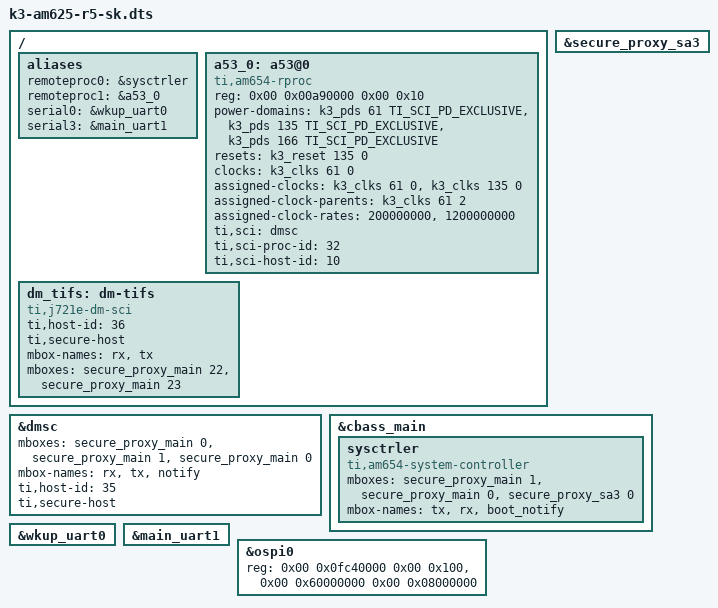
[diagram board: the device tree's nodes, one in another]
// SPDX-License-Identifier: GPL-2.0
/*
 * AM625 SK dts file for R5 SPL
 * Copyright (C) 2021-2022 Texas Instruments Incorporated - https://www.ti.com/
 */

#include "k3-am625-sk.dts"
#include "k3-am62x-sk-ddr4-1600MTs.dtsi"
#include "k3-am62-ddr.dtsi"

#include "k3-am625-sk-u-boot.dtsi"

/ {
	aliases {
		remoteproc0 = &sysctrler;
		remoteproc1 = &a53_0;
		serial0 = &wkup_uart0;
		serial3 = &main_uart1;
	};

	a53_0: a53@0 {
		compatible = "ti,am654-rproc";
		reg = <0x00 0x00a90000 0x00 0x10>;
		power-domains = <&k3_pds 61 TI_SCI_PD_EXCLUSIVE>,
				<&k3_pds 135 TI_SCI_PD_EXCLUSIVE>,
				<&k3_pds 166 TI_SCI_PD_EXCLUSIVE>;
		resets = <&k3_reset 135 0>;
		clocks = <&k3_clks 61 0>;
		assigned-clocks = <&k3_clks 61 0>, <&k3_clks 135 0>;
		assigned-clock-parents = <&k3_clks 61 2>;
		assigned-clock-rates = <200000000>, <1200000000>;
		ti,sci = <&dmsc>;
		ti,sci-proc-id = <32>;
		ti,sci-host-id = <10>;
		bootph-pre-ram;
	};

	dm_tifs: dm-tifs {
		compatible = "ti,j721e-dm-sci";
		ti,host-id = <36>;
		ti,secure-host;
		mbox-names = "rx", "tx";
		mboxes= <&secure_proxy_main 22>,
			<&secure_proxy_main 23>;
		bootph-pre-ram;
	};
};

&dmsc {
	mboxes= <&secure_proxy_main 0>,
		<&secure_proxy_main 1>,
		<&secure_proxy_main 0>;
	mbox-names = "rx", "tx", "notify";
	ti,host-id = <35>;
	ti,secure-host;
};

&secure_proxy_sa3 {
	/* We require this for boot handshake */
	status = "okay";
};

&cbass_main {
	sysctrler: sysctrler {
		compatible = "ti,am654-system-controller";
		mboxes= <&secure_proxy_main 1>, <&secure_proxy_main 0>, <&secure_proxy_sa3 0>;
		mbox-names = "tx", "rx", "boot_notify";
		bootph-pre-ram;
	};
};

/* WKUP UART0 is used for DM firmware logs */
&wkup_uart0 {
	status = "okay";
};

/* Main UART1 is used for TIFS firmware logs */
&main_uart1 {
	status = "okay";
};

&ospi0 {
	reg = <0x00 0x0fc40000 0x00 0x100>,
	      <0x00 0x60000000 0x00 0x08000000>;
};
